# MSP430F5529 register map
Vendor: msp430gen; File version: VERGEN_IDEMPOTENT_OUTPUT
Registers are 8-bit, read-write, reset 0x0 unless marked. A register's access mark holds for its fields unless they carry their own. Offsets are from the block's base; [hi:lo] are bit positions; {n}, {i} and the like mark numbered series; 'fields as' and 'values as' point back to an identical list.

## USB_CONTROL
Base 0x00000900
0x00 USBKEYID 16-bit — USB Controller key register
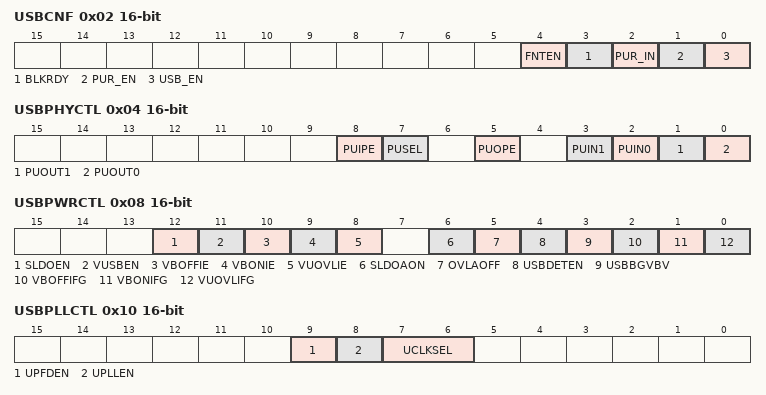
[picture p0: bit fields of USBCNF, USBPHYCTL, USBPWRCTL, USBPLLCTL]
0x02 USBCNF 16-bit — USB Module configuration register
  [4] FNTEN — USB - Frame Number receive Trigger enable for DMA
  [3] BLKRDY — USB - Block ready signal for DMA
  [2] PUR_IN — USB - PUR pin input value
  [1] PUR_EN — USB - PUR pin enable
  [0] USB_EN — USB - Module enable
0x04 USBPHYCTL 16-bit — USB PHY control register
  [8] PUIPE — USB - PHY Single Ended Input enable
  [7] PUSEL — USB - USB Port Function Select
  [5] PUOPE — USB - USB Port Output Enable
  [3] PUIN1 — USB - PU1/DM Input Data
  [2] PUIN0 — USB - PU0/DP Input Data
  [1] PUOUT1 — USB - USB Port Output Signal Bit 1
  [0] PUOUT0 — USB - USB Port Output Signal Bit 0
0x08 USBPWRCTL 16-bit — USB Power control register
  [12] SLDOEN — USB - Secondary LDO Enable (1.8V)
  [11] VUSBEN — USB - LDO Enable (3.3V)
  [10] VBOFFIE — USB - VBUS "Going OFF" Interrupt Enable
  [9] VBONIE — USB - VBUS "Coming ON" Interrupt Enable
  [8] VUOVLIE — USB - Overload indication Interrupt Enable
  [6] SLDOAON — USB - Secondary LDO auto on enable
  [5] OVLAOFF — USB - LDO overload auto off enable
  [4] USBDETEN — USB - VBUS on/off events enable
  [3] USBBGVBV — USB - USB Bandgap and VBUS valid
  [2] VBOFFIFG — USB - VBUS "Going OFF" Interrupt Flag
  [1] VBONIFG — USB - VBUS "Coming ON" Interrupt Flag
  [0] VUOVLIFG — USB - VUSB Overload Interrupt Flag
0x10 USBPLLCTL 16-bit — USB PLL control register
  [9] UPFDEN — USB - Phase Freq. Discriminator enable
  [8] UPLLEN — USB - PLL enable
  [7:6] UCLKSEL — USB - Module Clock Select Bit 0
    0=USB - Module Clock Select: 0; 1=USB - Module Clock Select: 1; 2=USB - Module Clock Select: 2; 3=USB - Module Clock Select: 3 (Reserved)
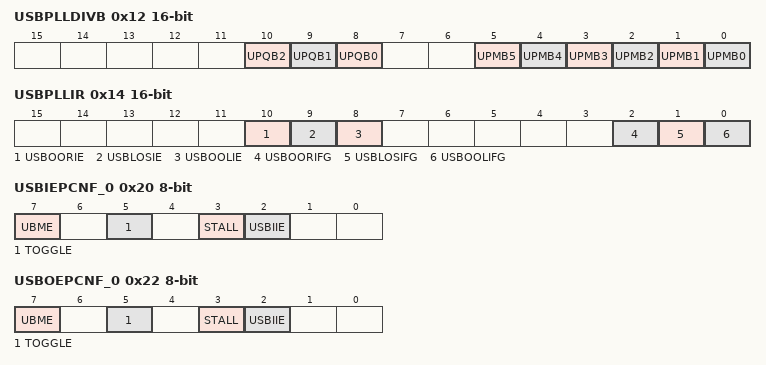
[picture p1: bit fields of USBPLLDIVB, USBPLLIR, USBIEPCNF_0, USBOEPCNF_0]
0x12 USBPLLDIVB 16-bit — USB PLL Clock Divider Buffer control register
  [10] UPQB2 — USB - PLL prescale divider buffer Bit 2
  [9] UPQB1 — USB - PLL prescale divider buffer Bit 1
  [8] UPQB0 — USB - PLL prescale divider buffer Bit 0
  [n] UPMB{n} (n=0..5) — USB - PLL feedback divider buffer Bit {n}
0x14 USBPLLIR 16-bit — USB PLL Interrupt control register
  [10] USBOORIE — USB - PLL out of range Interrupt enable
  [9] USBLOSIE — USB - PLL loss of signal Interrupt enable
  [8] USBOOLIE — USB - PLL out of lock Interrupt enable
  [2] USBOORIFG — USB - PLL out of range Interrupt Flag
  [1] USBLOSIFG — USB - PLL loss of signal Interrupt Flag
  [0] USBOOLIFG — USB - PLL out of lock Interrupt Flag
0x20 USBIEPCNF_0 — USB Input endpoint_0: Configuration
  [7] UBME — USB - UBM In-Endpoint Enable
  [5] TOGGLE — USB - Toggle Bit
  [3] STALL — USB - Stall Condition
  [2] USBIIE — USB - Transaction Interrupt indication enable
0x21 USBIEPCNT_0 — USB Input endpoint_0: Byte Count
0x22 USBOEPCNF_0 — USB Output endpoint_0: Configuration
  fields as USBIEPCNF_0
0x23 USBOEPCNT_0 — USB Output endpoint_0: byte count
0x2E USBIEPIE — USB Input endpoint interrupt enable flags
0x2F USBOEPIE — USB Output endpoint interrupt enable flags
0x30 USBIEPIFG — USB Input endpoint interrupt flags
0x31 USBOEPIFG — USB Output endpoint interrupt flags
0x32 USBVECINT 16-bit — USB Vector interrupt register
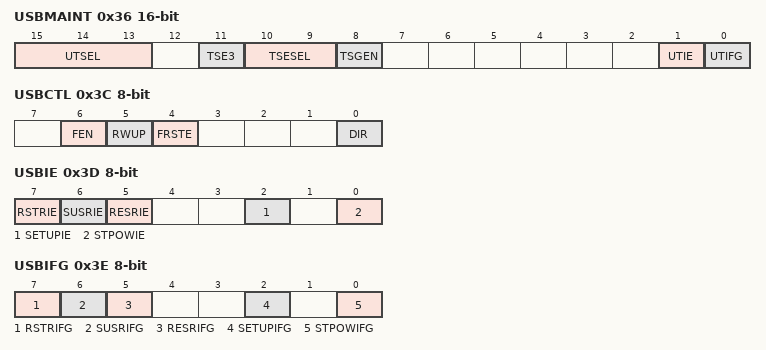
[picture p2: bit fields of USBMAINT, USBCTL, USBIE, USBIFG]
0x36 USBMAINT 16-bit — USB maintenance register
  [15:13] UTSEL — USB - Timer Select Bit 0
    {v}=USB - Timer Select: {v} (v=0..7)
  [11] TSE3 — USB - Time Stamp Event #3 Bit
  [10:9] TSESEL — USB - Time Stamp Event Select Bit 0
    {v}=USB - Time Stamp Event Select: {v} (v=0..3)
  [8] TSGEN — USB - Time Stamp Generator Enable
  [1] UTIE — USB - Timer Interrupt Enable
  [0] UTIFG — USB - Timer Interrupt Flag
0x38 USBTSREG 16-bit — USB Time Stamp register
0x3A USBFN 16-bit — USB Frame number
0x3C USBCTL — USB control register
  [6] FEN — USB - Function Enable Bit
  [5] RWUP — USB - Device Remote Wakeup Request
  [4] FRSTE — USB - Function Reset Connection Enable
  [0] DIR — USB - Data Response Bit
0x3D USBIE — USB interrupt enable register
  [7] RSTRIE — USB - Function Reset Request Interrupt Enable
  [6] SUSRIE — USB - Function Suspend Request Interrupt Enable
  [5] RESRIE — USB - Function Resume Request Interrupt Enable
  [2] SETUPIE — USB - Setup Interrupt Enable
  [0] STPOWIE — USB - Setup Overwrite Interrupt Enable
0x3E USBIFG — USB interrupt flag register
  [7] RSTRIFG — USB - Function Reset Request Interrupt Flag
  [6] SUSRIFG — USB - Function Suspend Request Interrupt Flag
  [5] RESRIFG — USB - Function Resume Request Interrupt Flag
  [2] SETUPIFG — USB - Setup Interrupt Flag
  [0] STPOWIFG — USB - Setup Overwrite Interrupt Flag
0x3F USBFUNADR — USB Function address register
